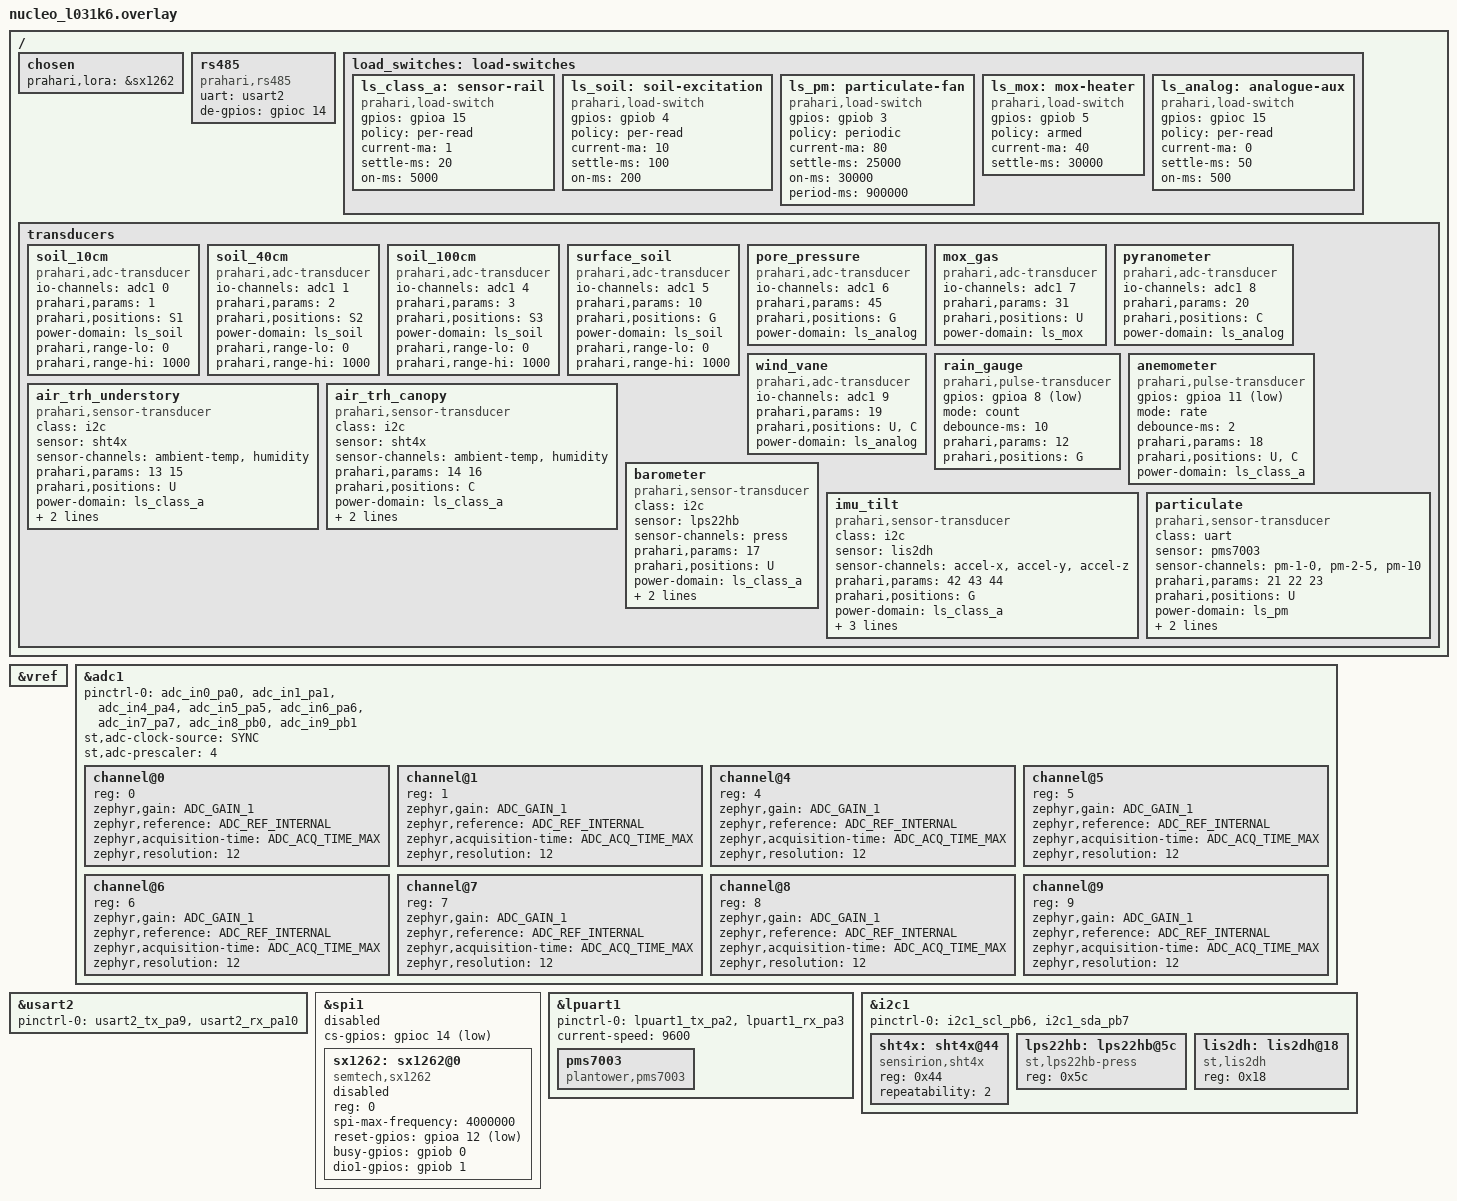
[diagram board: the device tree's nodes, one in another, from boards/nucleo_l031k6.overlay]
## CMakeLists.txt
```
# PRAHARI Code A — pod firmware (L1).  One image for every pod position.
# SPDX-License-Identifier: Apache-2.0
cmake_minimum_required(VERSION 3.20.0)
find_package(Zephyr REQUIRED HINTS $ENV{ZEPHYR_BASE})
project(prahari_pod LANGUAGES C)

target_include_directories(app PRIVATE include)

# Hardware-independent modules (also compiled into the ztest suites).
target_sources(app PRIVATE
  src/pod_position.c
  src/xdcr.c
  src/power.c
  src/pulse.c
  src/sampler.c
  src/calib.c
  src/median5.c
  src/zgate.c
  src/derive.c
  src/pipeline.c
  src/wire.c
  src/rs485.c
  src/lora_slot.c
  src/link_cfg.c
)

# Exactly one head-node link (blueprint §4.4).
target_sources_ifdef(CONFIG_PRAHARI_LINK_MODE_W app PRIVATE src/link_w.c)
target_sources_ifdef(CONFIG_PRAHARI_LINK_MODE_R app PRIVATE src/link_r.c)

# Devicetree-generated tables, class drivers and the boot/sampling loop.
target_sources(app PRIVATE
  src/pod_dt_tables.c
  src/drivers/xdcr_adc.c
  src/drivers/xdcr_pulse.c
  src/drivers/xdcr_sensor.c
  src/main.c
)
```

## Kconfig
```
# PRAHARI Code A — pod firmware configuration.
# SPDX-License-Identifier: Apache-2.0

mainmenu "PRAHARI pod firmware (Code A)"

choice PRAHARI_POD_POSITION_DEFAULT
	prompt "Default pod position"
	default PRAHARI_POD_POSITION_DEFAULT_S1
	help
	  Compile-time position used when no valid position block is found in
	  EEPROM (or EEPROM lookup is disabled).  Blueprint §4.1: six positions,
	  one design.  The transducer set for each position comes from the
	  devicetree 'prahari,positions' property of every transducer node.

config PRAHARI_POD_POSITION_DEFAULT_S1
	bool "S1  (-10 cm, potted)"
config PRAHARI_POD_POSITION_DEFAULT_S2
	bool "S2  (-40 cm, potted)"
config PRAHARI_POD_POSITION_DEFAULT_S3
	bool "S3  (-100 cm, potted)"
config PRAHARI_POD_POSITION_DEFAULT_G
	bool "G   (ground, 0 m)"
config PRAHARI_POD_POSITION_DEFAULT_U
	bool "U   (understory, ~2 m)"
config PRAHARI_POD_POSITION_DEFAULT_C
	bool "C   (canopy / mast top, ~10 m)"
endchoice

config PRAHARI_POD_POSITION_FROM_EEPROM
	bool "Read pod position from the EEPROM config block at boot"
	default y
	depends on EEPROM
	help
	  Boot-time selection: a 5-byte block at EEPROM offset 0
	  ('P','D', version, position, CRC-8).  Falls back to the Kconfig
	  default when the block is blank or fails validation.

config PRAHARI_SAMPLE_PERIOD_S
	int "Acquisition cadence for per-read transducers (seconds)"
	range 1 3600
	default 60
	help
	  Blueprint §4.3 "sample at configured cadence".  Transducers on a
	  'periodic' load switch (e.g. the particulate fan) are read on their
	  own duty cycle from §3.4 instead.

config PRAHARI_RAIL_BUDGET_MA
	int "Switched 3.3 V rail budget (mA), 0 = unenforced"
	default 0
	help
	  Upper bound on the summed active current of all load switches that
	  are on at once.  Not specified in the blueprint; set it from the pod
	  board's 12 V -> 3.3 V buck rating once that is chosen.  A request
	  that would exceed the budget is refused (-EBUSY); periodic windows
	  are deferred to the next tick.

config PRAHARI_MOX_ARMED_AT_BOOT
	bool "Arm MOX gas heater(s) at boot"
	default n
	help
	  Blueprint §3.4: the MOX heater is "on only when armed".  Arming is
	  meant to come from the head node; this only sets the boot state.

config PRAHARI_MAX_CHANNELS
	int "Maximum in-situ channels one pod processes"
	range 4 32
	default 12
	help
	  Sizes the median-of-5 and z-score windows (RAM).  A pod position
	  with more parameters than this fails pipeline init.

config PRAHARI_ZGATE_WINDOW
	int "Anomaly-gate rolling window (samples)"
	range 4 32
	default 12
	help
	  Blueprint §4.3: z-score against a rolling mean.  At the default
	  60 s cadence this is 12 minutes — the only history the pod keeps.

config PRAHARI_ZGATE_THRESHOLD_CENTI
	int "Anomaly-gate |z| threshold, hundredths"
	default 300

config PRAHARI_ZGATE_STD_FLOOR_PERMILLE
	int "Anomaly-gate std floor as permille of |mean|"
	default 10
	help
	  Keeps a flat signal from making every LSB of noise a 'z = inf'
	  anomaly.  Absolute floor is 1 milli-unit.

config PRAHARI_EEPROM_CALIB_OFFSET
	int "EEPROM offset of the calibration table"
	default 16
	help
	  Blueprint §4.3: two-point coefficients in EEPROM.  Table format in
	  include/prahari/calib.h; up to 16 entries (277 bytes).

choice PRAHARI_LINK_MODE
	prompt "Head-node link (blueprint §4.4)"
	default PRAHARI_LINK_MODE_W
	help
	  A pod is wired OR radio, set by whether it can power itself (§4.4).
	  Exactly one link stack is built into the image.

config PRAHARI_LINK_MODE_W
	bool "Mode W — wired: RS-485 half-duplex multi-drop, polled slave"
	select UART_INTERRUPT_DRIVEN
	help
	  Head node is bus master (§5.2 sweep).  Needs an enabled /rs485
	  node (prahari,rs485) in the board overlay.

config PRAHARI_LINK_MODE_R
	bool "Mode R — radio: LoRa SX1262, scheduled slot"
	select SPI
	select LORA
	help
	  Reports in a TDMA slot after the head node's beacon.  Needs an
	  enabled semtech,sx1262 node named by 'chosen prahari,lora'.
endchoice

config PRAHARI_LINK_ADDR
	int "Default RS-485 address / pod identity (1..247)"
	range 1 247
	default 1
	help
	  Overridden by the EEPROM link block ('L','K') when present.

config PRAHARI_LINK_SLOT
	int "Default TDMA slot (Mode R)"
	range 0 255
	default 0

config PRAHARI_RS485_IDLE_GAP_MS
	int "RS-485 inter-frame idle gap that resets the parser (ms)"
	default 20
	depends on PRAHARI_LINK_MODE_W

if PRAHARI_LINK_MODE_R

config PRAHARI_LORA_FREQ_HZ
	int "LoRa centre frequency (Hz)"
	default 866000000
	help
	  §6.2 / §7.3: 865-867 MHz ISM, licence-free in India.

config PRAHARI_LORA_SF
	int "LoRa spreading factor"
	range 7 10
	default 9
	help
	  §7.3: SF7-SF10, 125 kHz.  Fixed per pod; adaptive SF is the head node's call.

config PRAHARI_LORA_TX_DBM
	int "LoRa TX power (dBm)"
	default 14

config PRAHARI_SLOT_SUPERFRAME_MS
	int "TDMA superframe (ms)"
	default 60000
	help
	  One round per acquisition cadence.

config PRAHARI_SLOT_MS
	int "Slot length (ms)"
	default 2000
	help
	  A full pod report (~110 B) at SF10/125 kHz is ~0.8 s on air.

config PRAHARI_SLOT_N
	int "Number of pod slots per superframe"
	default 8

config PRAHARI_SLOT_BEACON_MS
	int "Beacon airtime reserved at superframe start (ms)"
	default 500

config PRAHARI_SLOT_GUARD_MS
	int "Guard time around slot edges (ms)"
	default 50

config PRAHARI_SLOT_HOLDOVER_MS
	int "Time without a beacon before the pod counts as unsynced (ms)"
	default 3600000
	help
	  The pod keeps its free-running schedule regardless; this only
	  changes what it reports about itself.

endif # PRAHARI_LINK_MODE_R

config PRAHARI_FRAME_PRINT
	bool "Print each completed frame on the console"
	default y
	depends on PRINTK

# The SX1262 is driven by Zephyr's native backend (no loramac-node /
# lora-basics-modem module in this workspace).  The legacy module-backed
# driver symbol defaults on whenever the DT node exists; keep it off.
configdefault LORA_SX126X
	default n

source "Kconfig.zephyr"
```

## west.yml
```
# West manifest for PRAHARI Code A — pod firmware (L1).
#
# Topology: T2 ("application as manifest repository").  The workspace root
# is code_a_pod_firmware/; this directory (app/) is the manifest repo and
# the Zephyr application.  Zephyr itself and the HAL modules are checked
# out as siblings of app/ by `west update` and are NOT part of the
# deliverable source.
#
# Zephyr v4.4.2 — newest stable tag at time of setup (2026-09-09);
# 4.4 is the first release of the new six-month cadence and the LTS
# candidate.  Pinned to a tag, never a branch.  Requires Zephyr SDK 1.0.1
# (zephyr/SDK_VERSION).
#
# Only the modules the STM32L0 pod target needs are imported.  Add to the
# allowlist deliberately; do not remove it.
manifest:
  remotes:
    - name: zephyrproject-rtos
      url-base: https://github.com/zephyrproject-rtos

  projects:
    - name: zephyr
      remote: zephyrproject-rtos
      revision: v4.4.2
      import:
        name-allowlist:
          - cmsis        # legacy CMSIS headers, still referenced by hal_stm32
          - cmsis_6      # CMSIS 6 core headers used by Zephyr arch/arm
          - hal_stm32    # STM32Cube LL/HAL + dts pinctrl for STM32L0

  self:
    path: app
```

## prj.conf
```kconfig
# PRAHARI Code A — base configuration (all positions, one image).
CONFIG_GPIO=y
CONFIG_ADC=y
CONFIG_I2C=y
CONFIG_SERIAL=y
CONFIG_SENSOR=y
CONFIG_EEPROM=y

# Keep the image small: STM32L031 has 32 KB flash / 8 KB RAM.
CONFIG_SIZE_OPTIMIZATIONS=y
CONFIG_MAIN_STACK_SIZE=1280
CONFIG_ISR_STACK_SIZE=512
CONFIG_IDLE_STACK_SIZE=256
CONFIG_SYSTEM_WORKQUEUE_STACK_SIZE=512
CONFIG_LOG=n
CONFIG_PRINTK=y
CONFIG_CONSOLE=y
CONFIG_UART_CONSOLE=y
CONFIG_ASSERT=n
```

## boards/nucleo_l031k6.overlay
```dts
/*
 * PRAHARI pod firmware on the STM32L031K6 Nucleo-32 (SoC = blueprint §4.2).
 *
 * ONE image, all six positions: every transducer that any position can
 * carry is declared here; the firmware enables only those whose
 * "prahari,positions" includes the pod's resolved position.
 *
 * Reference parts (NOT a BOM decision — swap the sensor node, keep the
 * transducer node): SHT4x air T/RH, LPS22HB pressure, LIS2DH accel/tilt,
 * PMS7003 particulate.  Analogue inputs are generic.
 *
 * Pin plan (Nucleo-32): USART2 on PA9/PA10 carries the RS-485 transceiver
 * (Mode W) — and the console in this dev build, which on real hardware
 * must be off (-DCONFIG_UART_CONSOLE=n) so printk never hits the bus.
 * LPUART1 PA2/PA3 = particulate sensor.  I2C1 PB6/PB7.  RS-485 DE PC14.
 *
 * Mode R on this 32-pin package needs SPI1 PA5/6/7 + PA12/PB0/PB1, which
 * the ADC population uses: boards/nucleo_l031k6_mode_r.overlay
 * (EXTRA_DTC_OVERLAY_FILE) enables the radio and disables those
 * transducers.  The real L051 pod board is pinned out for its population.
 *
 * SPDX-License-Identifier: Apache-2.0
 */
#include <zephyr/dt-bindings/adc/adc.h>
#include <zephyr/dt-bindings/gpio/gpio.h>

/ {
	chosen {
		prahari,lora = &sx1262;
	};

	/* Mode W transceiver: DE/RE on PC14 (LSE pin, unused as oscillator). */
	rs485: rs485 {
		compatible = "prahari,rs485";
		uart = <&usart2>;
		de-gpios = <&gpioc 14 GPIO_ACTIVE_HIGH>;
	};

	/* Blueprint §3.4 switched rails.  Child index = power-domain number. */
	load_switches: load-switches {
		ls_class_a: sensor-rail {
			/* Air T/RH, pressure, IMU: <1 mA.  §3.4 says "continuous is
			 * acceptable" but the rule is nothing energised between reads,
			 * so per-read here; change policy to "hold" to keep it up. */
			compatible = "prahari,load-switch";
			gpios = <&gpioa 15 GPIO_ACTIVE_HIGH>;
			policy = "per-read";
			current-ma = <1>;
			settle-ms = <20>;
			on-ms = <5000>;
		};
		ls_soil: soil-excitation {
			/* §3.4: ~10 mA, 200 ms per read */
			compatible = "prahari,load-switch";
			gpios = <&gpiob 4 GPIO_ACTIVE_HIGH>;
			policy = "per-read";
			current-ma = <10>;
			settle-ms = <100>;
			on-ms = <200>;
		};
		ls_pm: particulate-fan {
			/* §3.4: ~80 mA, 30 s every 15 min.  Read at 25 s, off at 30 s. */
			compatible = "prahari,load-switch";
			gpios = <&gpiob 3 GPIO_ACTIVE_HIGH>;   /* Nucleo LD3: fan window visible */
			policy = "periodic";
			current-ma = <80>;
			settle-ms = <25000>;
			on-ms = <30000>;
			period-ms = <900000>;
		};
		ls_mox: mox-heater {
			/* §3.4: ~40 mA, on only when armed.  Warm-up not specified in
			 * the blueprint: 30 s is a placeholder for the chosen element. */
			compatible = "prahari,load-switch";
			gpios = <&gpiob 5 GPIO_ACTIVE_HIGH>;
			policy = "armed";
			current-ma = <40>;
			settle-ms = <30000>;
		};
		ls_analog: analogue-aux {
			/* Pore-pressure, wind vane, pyranometer front-ends.  Draw not in
			 * §3.4 table (0 = unbudgeted until the parts are chosen). */
			compatible = "prahari,load-switch";
			gpios = <&gpioc 15 GPIO_ACTIVE_HIGH>;
			policy = "per-read";
			current-ma = <0>;
			settle-ms = <50>;
			on-ms = <500>;
		};
	};

	/* Parameter IDs: docs/reference/prahari_parameters.md (P-numbers). */
	transducers: transducers {
		/* ---- class C: analogue into ADC ---- */
		soil_10cm {
			/* Capacitive probe lead 1 -> P1.  P4/P7 (temp, EC) need extra
			 * analogue lines or a digital probe: add io-channels + params. */
			compatible = "prahari,adc-transducer";
			io-channels = <&adc1 0>;
			prahari,params = <1>;
			prahari,positions = "S1";
			power-domain = <&ls_soil>;
			prahari,range-lo = <0>;
			prahari,range-hi = <1000>;
		};
		soil_40cm {
			compatible = "prahari,adc-transducer";
			io-channels = <&adc1 1>;
			prahari,params = <2>;
			prahari,positions = "S2";
			power-domain = <&ls_soil>;
			prahari,range-lo = <0>;
			prahari,range-hi = <1000>;
		};
		soil_100cm {
			compatible = "prahari,adc-transducer";
			io-channels = <&adc1 4>;
			prahari,params = <3>;
			prahari,positions = "S3";
			power-domain = <&ls_soil>;
			prahari,range-lo = <0>;
			prahari,range-hi = <1000>;
		};
		surface_soil {
			/* §11.4 G: surface soil moisture 0-5 cm -> P10 */
			compatible = "prahari,adc-transducer";
			io-channels = <&adc1 5>;
			prahari,params = <10>;
			prahari,positions = "G";
			power-domain = <&ls_soil>;
			prahari,range-lo = <0>;
			prahari,range-hi = <1000>;
		};
		pore_pressure {
			/* Requested at G; blueprint §11.4 lists it on the R3 slope pod. */
			compatible = "prahari,adc-transducer";
			io-channels = <&adc1 6>;
			prahari,params = <45>;
			prahari,positions = "G";
			power-domain = <&ls_analog>;
		};
		mox_gas {
			/* Analogue MOX element (blueprint class C variant) -> P31 TVOC
			 * index after calibration.  Heater on the armed rail. */
			compatible = "prahari,adc-transducer";
			io-channels = <&adc1 7>;
			prahari,params = <31>;
			prahari,positions = "U";
			power-domain = <&ls_mox>;
		};
		pyranometer {
			/* Global solar irradiance -> P20 (canopy, needs open sky) */
			compatible = "prahari,adc-transducer";
			io-channels = <&adc1 8>;
			prahari,params = <20>;
			prahari,positions = "C";
			power-domain = <&ls_analog>;
		};
		wind_vane {
			/* CONFLICT FLAGGED: blueprint §3.1 lists the wind vane under class
			 * D (pulse); a potentiometer vane is analogue.  Modelled as class C
			 * here; change compatible to prahari,pulse-transducer if the chosen
			 * vane is an encoder.  Bearing -> sin/cos happens downstream. */
			compatible = "prahari,adc-transducer";
			io-channels = <&adc1 9>;
			prahari,params = <19>;
			prahari,positions = "U", "C";
			power-domain = <&ls_analog>;
		};

		/* ---- class D: pulse / interrupt ---- */
		rain_gauge {
			/* Tipping bucket -> P12 accumulation (tips; mm at calibration).
			 * No power-domain on purpose: §3.4 passive, never switched. */
			compatible = "prahari,pulse-transducer";
			gpios = <&gpioa 8 (GPIO_PULL_UP | GPIO_ACTIVE_LOW)>;
			mode = "count";
			debounce-ms = <10>;
			prahari,params = <12>;
			prahari,positions = "G";
		};
		anemometer {
			/* Cup anemometer reed switch -> P18 (pulses per cycle; m/s at cal) */
			compatible = "prahari,pulse-transducer";
			gpios = <&gpioa 11 (GPIO_PULL_UP | GPIO_ACTIVE_LOW)>;
			mode = "rate";
			debounce-ms = <2>;
			prahari,params = <18>;
			prahari,positions = "U", "C";
			power-domain = <&ls_class_a>;
		};

		/* ---- class A: I2C sensors (each pod terminates its own bus) ---- */
		air_trh_understory {
			/* Same physical part as air_trh_canopy; which node is active
			 * depends on position, so P13/P15 vs P14/P16 is a config fact. */
			compatible = "prahari,sensor-transducer";
			class = "i2c";
			sensor = <&sht4x>;
			sensor-channels = "ambient-temp", "humidity";
			prahari,params = <13 15>;
			prahari,positions = "U";
			power-domain = <&ls_class_a>;
			prahari,range-lo = <(-40000) 0>;
			prahari,range-hi = <60000 100000>;
		};
		air_trh_canopy {
			compatible = "prahari,sensor-transducer";
			class = "i2c";
			sensor = <&sht4x>;
			sensor-channels = "ambient-temp", "humidity";
			prahari,params = <14 16>;
			prahari,positions = "C";
			power-domain = <&ls_class_a>;
			prahari,range-lo = <(-40000) 0>;
			prahari,range-hi = <60000 100000>;
		};
		barometer {
			compatible = "prahari,sensor-transducer";
			class = "i2c";
			sensor = <&lps22hb>;
			sensor-channels = "press";
			prahari,params = <17>;
			prahari,positions = "U";
			power-domain = <&ls_class_a>;
			prahari,range-lo = <300000>;
			prahari,range-hi = <1100000>;
		};
		imu_tilt {
			/* Bonded to the mast foot: measures the mast, not the air (§3.2) */
			compatible = "prahari,sensor-transducer";
			class = "i2c";
			sensor = <&lis2dh>;
			sensor-channels = "accel-x", "accel-y", "accel-z";
			prahari,params = <42 43 44>;
			prahari,positions = "G";
			power-domain = <&ls_class_a>;
			prahari,range-lo = <(-2000000) (-2000000) (-2000000)>;
			prahari,range-hi = <2000000 2000000 2000000>;
		};

		/* ---- class B: UART ---- */
		particulate {
			compatible = "prahari,sensor-transducer";
			class = "uart";
			sensor = <&pms7003>;
			sensor-channels = "pm-1-0", "pm-2-5", "pm-10";
			prahari,params = <21 22 23>;
			prahari,positions = "U";
			power-domain = <&ls_pm>;
			prahari,range-lo = <0 0 0>;
			prahari,range-hi = <1000000 1000000 1000000>;
		};
	};
};

/* Own supply rail (§4.3 self-report) via the internal reference. */
&vref {
	status = "okay";
};

&adc1 {
	pinctrl-0 = <&adc_in0_pa0 &adc_in1_pa1 &adc_in4_pa4 &adc_in5_pa5
		     &adc_in6_pa6 &adc_in7_pa7 &adc_in8_pb0 &adc_in9_pb1>;
	pinctrl-names = "default";
	st,adc-clock-source = "SYNC";
	st,adc-prescaler = <4>;
	status = "okay";
	#address-cells = <1>;
	#size-cells = <0>;

	channel@0 { reg = <0>; zephyr,gain = "ADC_GAIN_1"; zephyr,reference = "ADC_REF_INTERNAL";
		    zephyr,acquisition-time = <ADC_ACQ_TIME_MAX>; zephyr,resolution = <12>; };
	channel@1 { reg = <1>; zephyr,gain = "ADC_GAIN_1"; zephyr,reference = "ADC_REF_INTERNAL";
		    zephyr,acquisition-time = <ADC_ACQ_TIME_MAX>; zephyr,resolution = <12>; };
	channel@4 { reg = <4>; zephyr,gain = "ADC_GAIN_1"; zephyr,reference = "ADC_REF_INTERNAL";
		    zephyr,acquisition-time = <ADC_ACQ_TIME_MAX>; zephyr,resolution = <12>; };
	channel@5 { reg = <5>; zephyr,gain = "ADC_GAIN_1"; zephyr,reference = "ADC_REF_INTERNAL";
		    zephyr,acquisition-time = <ADC_ACQ_TIME_MAX>; zephyr,resolution = <12>; };
	channel@6 { reg = <6>; zephyr,gain = "ADC_GAIN_1"; zephyr,reference = "ADC_REF_INTERNAL";
		    zephyr,acquisition-time = <ADC_ACQ_TIME_MAX>; zephyr,resolution = <12>; };
	channel@7 { reg = <7>; zephyr,gain = "ADC_GAIN_1"; zephyr,reference = "ADC_REF_INTERNAL";
		    zephyr,acquisition-time = <ADC_ACQ_TIME_MAX>; zephyr,resolution = <12>; };
	channel@8 { reg = <8>; zephyr,gain = "ADC_GAIN_1"; zephyr,reference = "ADC_REF_INTERNAL";
		    zephyr,acquisition-time = <ADC_ACQ_TIME_MAX>; zephyr,resolution = <12>; };
	channel@9 { reg = <9>; zephyr,gain = "ADC_GAIN_1"; zephyr,reference = "ADC_REF_INTERNAL";
		    zephyr,acquisition-time = <ADC_ACQ_TIME_MAX>; zephyr,resolution = <12>; };
};

/* Console off the VCP pins so LPUART1 can take PA2/PA3. */
&usart2 {
	pinctrl-0 = <&usart2_tx_pa9 &usart2_rx_pa10>;
	pinctrl-names = "default";
};

/* SPI1 shares PA5/6/7 with ADC in5/6/7: off unless the Mode R overlay
 * enables it (and disables those ADC transducers). */
&spi1 {
	status = "disabled";
	cs-gpios = <&gpioc 14 GPIO_ACTIVE_LOW>;

	sx1262: sx1262@0 {
		compatible = "semtech,sx1262";
		reg = <0>;
		spi-max-frequency = <4000000>;
		reset-gpios = <&gpioa 12 GPIO_ACTIVE_LOW>;
		busy-gpios = <&gpiob 0 GPIO_ACTIVE_HIGH>;
		dio1-gpios = <&gpiob 1 GPIO_ACTIVE_HIGH>;
		status = "disabled";
	};
};

&lpuart1 {
	pinctrl-0 = <&lpuart1_tx_pa2 &lpuart1_rx_pa3>;
	pinctrl-names = "default";
	current-speed = <9600>;
	status = "okay";

	pms7003: pms7003 {
		compatible = "plantower,pms7003";
	};
};

&i2c1 {
	pinctrl-0 = <&i2c1_scl_pb6 &i2c1_sda_pb7>;
	pinctrl-names = "default";
	status = "okay";

	sht4x: sht4x@44 {
		compatible = "sensirion,sht4x";
		reg = <0x44>;
		repeatability = <2>;
	};
	lps22hb: lps22hb@5c {
		compatible = "st,lps22hb-press";
		reg = <0x5c>;
	};
	lis2dh: lis2dh@18 {
		compatible = "st,lis2dh";
		reg = <0x18>;
	};
};
```

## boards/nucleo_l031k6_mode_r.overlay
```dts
/*
 * Mode R on the Nucleo-32 L031K6: EXTRA_DTC_OVERLAY_FILE for
 * -DCONFIG_PRAHARI_LINK_MODE_R=y.  The 32-pin package cannot carry the
 * whole dev population plus a radio, so the transducers on the SPI /
 * control pins are disabled here.  Dev-board limitation only.
 * SPDX-License-Identifier: Apache-2.0
 */
&spi1 {
	status = "okay";
};

&sx1262 {
	status = "okay";
};

&rs485 {
	status = "disabled";
};

&adc1 {
	pinctrl-0 = <&adc_in0_pa0 &adc_in1_pa1 &adc_in4_pa4>;
};

&{/transducers/surface_soil} { status = "disabled"; };
&{/transducers/pore_pressure} { status = "disabled"; };
&{/transducers/mox_gas} { status = "disabled"; };
&{/transducers/pyranometer} { status = "disabled"; };
&{/transducers/wind_vane} { status = "disabled"; };
```

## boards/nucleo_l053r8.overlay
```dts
/*
 * SIZE STAND-IN ONLY: same population as nucleo_l031k6 on the Nucleo-64
 * L053R8 (64 KB flash, same L0 family) to measure the image on a 64 KB part
 * until the L051 decision and its custom board definition exist.  Not a
 * target.  Enough pins here for both link modes without disabling anything.
 *
 * ONE image, all six positions: every transducer that any position can
 * carry is declared here; the firmware enables only those whose
 * "prahari,positions" includes the pod's resolved position.
 *
 * Reference parts (NOT a BOM decision — swap the sensor node, keep the
 * transducer node): SHT4x air T/RH, LPS22HB pressure, LIS2DH accel/tilt,
 * PMS7003 particulate.  Analogue inputs are generic.
 *
 * Pin plan (Nucleo-32): USART2 on PA9/PA10 carries the RS-485 transceiver
 * (Mode W) — and the console in this dev build, which on real hardware
 * must be off (-DCONFIG_UART_CONSOLE=n) so printk never hits the bus.
 * LPUART1 PA2/PA3 = particulate sensor.  I2C1 PB6/PB7.  RS-485 DE PC14.
 *
 * Mode R on this 32-pin package needs SPI1 PA5/6/7 + PA12/PB0/PB1, which
 * the ADC population uses: boards/nucleo_l031k6_mode_r.overlay
 * (EXTRA_DTC_OVERLAY_FILE) enables the radio and disables those
 * transducers.  The real L051 pod board is pinned out for its population.
 *
 * SPDX-License-Identifier: Apache-2.0
 */
#include <zephyr/dt-bindings/adc/adc.h>
#include <zephyr/dt-bindings/gpio/gpio.h>

/ {
	chosen {
		prahari,lora = &sx1262;
	};

	/* Mode W transceiver: DE/RE on PC14 (LSE pin, unused as oscillator). */
	rs485: rs485 {
		compatible = "prahari,rs485";
		uart = <&usart1>;
		de-gpios = <&gpioc 8 GPIO_ACTIVE_HIGH>;
	};

	/* Blueprint §3.4 switched rails.  Child index = power-domain number. */
	load_switches: load-switches {
		ls_class_a: sensor-rail {
			/* Air T/RH, pressure, IMU: <1 mA.  §3.4 says "continuous is
			 * acceptable" but the rule is nothing energised between reads,
			 * so per-read here; change policy to "hold" to keep it up. */
			compatible = "prahari,load-switch";
			gpios = <&gpioa 15 GPIO_ACTIVE_HIGH>;
			policy = "per-read";
			current-ma = <1>;
			settle-ms = <20>;
			on-ms = <5000>;
		};
		ls_soil: soil-excitation {
			/* §3.4: ~10 mA, 200 ms per read */
			compatible = "prahari,load-switch";
			gpios = <&gpiob 4 GPIO_ACTIVE_HIGH>;
			policy = "per-read";
			current-ma = <10>;
			settle-ms = <100>;
			on-ms = <200>;
		};
		ls_pm: particulate-fan {
			/* §3.4: ~80 mA, 30 s every 15 min.  Read at 25 s, off at 30 s. */
			compatible = "prahari,load-switch";
			gpios = <&gpiob 3 GPIO_ACTIVE_HIGH>;   /* Nucleo LD3: fan window visible */
			policy = "periodic";
			current-ma = <80>;
			settle-ms = <25000>;
			on-ms = <30000>;
			period-ms = <900000>;
		};
		ls_mox: mox-heater {
			/* §3.4: ~40 mA, on only when armed.  Warm-up not specified in
			 * the blueprint: 30 s is a placeholder for the chosen element. */
			compatible = "prahari,load-switch";
			gpios = <&gpiob 5 GPIO_ACTIVE_HIGH>;
			policy = "armed";
			current-ma = <40>;
			settle-ms = <30000>;
		};
		ls_analog: analogue-aux {
			/* Pore-pressure, wind vane, pyranometer front-ends.  Draw not in
			 * §3.4 table (0 = unbudgeted until the parts are chosen). */
			compatible = "prahari,load-switch";
			gpios = <&gpioc 15 GPIO_ACTIVE_HIGH>;
			policy = "per-read";
			current-ma = <0>;
			settle-ms = <50>;
			on-ms = <500>;
		};
	};

	/* Parameter IDs: docs/reference/prahari_parameters.md (P-numbers). */
	transducers: transducers {
		/* ---- class C: analogue into ADC ---- */
		soil_10cm {
			/* Capacitive probe lead 1 -> P1.  P4/P7 (temp, EC) need extra
			 * analogue lines or a digital probe: add io-channels + params. */
			compatible = "prahari,adc-transducer";
			io-channels = <&adc1 0>;
			prahari,params = <1>;
			prahari,positions = "S1";
			power-domain = <&ls_soil>;
			prahari,range-lo = <0>;
			prahari,range-hi = <1000>;
		};
		soil_40cm {
			compatible = "prahari,adc-transducer";
			io-channels = <&adc1 1>;
			prahari,params = <2>;
			prahari,positions = "S2";
			power-domain = <&ls_soil>;
			prahari,range-lo = <0>;
			prahari,range-hi = <1000>;
		};
		soil_100cm {
			compatible = "prahari,adc-transducer";
			io-channels = <&adc1 4>;
			prahari,params = <3>;
			prahari,positions = "S3";
			power-domain = <&ls_soil>;
			prahari,range-lo = <0>;
			prahari,range-hi = <1000>;
		};
		surface_soil {
			/* §11.4 G: surface soil moisture 0-5 cm -> P10 */
			compatible = "prahari,adc-transducer";
			io-channels = <&adc1 5>;
			prahari,params = <10>;
			prahari,positions = "G";
			power-domain = <&ls_soil>;
			prahari,range-lo = <0>;
			prahari,range-hi = <1000>;
		};
		pore_pressure {
			/* Requested at G; blueprint §11.4 lists it on the R3 slope pod. */
			compatible = "prahari,adc-transducer";
			io-channels = <&adc1 6>;
			prahari,params = <45>;
			prahari,positions = "G";
			power-domain = <&ls_analog>;
		};
		mox_gas {
			/* Analogue MOX element (blueprint class C variant) -> P31 TVOC
			 * index after calibration.  Heater on the armed rail. */
			compatible = "prahari,adc-transducer";
			io-channels = <&adc1 7>;
			prahari,params = <31>;
			prahari,positions = "U";
			power-domain = <&ls_mox>;
		};
		pyranometer {
			/* Global solar irradiance -> P20 (canopy, needs open sky) */
			compatible = "prahari,adc-transducer";
			io-channels = <&adc1 8>;
			prahari,params = <20>;
			prahari,positions = "C";
			power-domain = <&ls_analog>;
		};
		wind_vane {
			/* CONFLICT FLAGGED: blueprint §3.1 lists the wind vane under class
			 * D (pulse); a potentiometer vane is analogue.  Modelled as class C
			 * here; change compatible to prahari,pulse-transducer if the chosen
			 * vane is an encoder.  Bearing -> sin/cos happens downstream. */
			compatible = "prahari,adc-transducer";
			io-channels = <&adc1 9>;
			prahari,params = <19>;
			prahari,positions = "U", "C";
			power-domain = <&ls_analog>;
		};

		/* ---- class D: pulse / interrupt ---- */
		rain_gauge {
			/* Tipping bucket -> P12 accumulation (tips; mm at calibration).
			 * No power-domain on purpose: §3.4 passive, never switched. */
			compatible = "prahari,pulse-transducer";
			gpios = <&gpioa 8 (GPIO_PULL_UP | GPIO_ACTIVE_LOW)>;
			mode = "count";
			debounce-ms = <10>;
			prahari,params = <12>;
			prahari,positions = "G";
		};
		anemometer {
			/* Cup anemometer reed switch -> P18 (pulses per cycle; m/s at cal) */
			compatible = "prahari,pulse-transducer";
			gpios = <&gpioa 11 (GPIO_PULL_UP | GPIO_ACTIVE_LOW)>;
			mode = "rate";
			debounce-ms = <2>;
			prahari,params = <18>;
			prahari,positions = "U", "C";
			power-domain = <&ls_class_a>;
		};

		/* ---- class A: I2C sensors (each pod terminates its own bus) ---- */
		air_trh_understory {
			/* Same physical part as air_trh_canopy; which node is active
			 * depends on position, so P13/P15 vs P14/P16 is a config fact. */
			compatible = "prahari,sensor-transducer";
			class = "i2c";
			sensor = <&sht4x>;
			sensor-channels = "ambient-temp", "humidity";
			prahari,params = <13 15>;
			prahari,positions = "U";
			power-domain = <&ls_class_a>;
			prahari,range-lo = <(-40000) 0>;
			prahari,range-hi = <60000 100000>;
		};
		air_trh_canopy {
			compatible = "prahari,sensor-transducer";
			class = "i2c";
			sensor = <&sht4x>;
			sensor-channels = "ambient-temp", "humidity";
			prahari,params = <14 16>;
			prahari,positions = "C";
			power-domain = <&ls_class_a>;
			prahari,range-lo = <(-40000) 0>;
			prahari,range-hi = <60000 100000>;
		};
		barometer {
			compatible = "prahari,sensor-transducer";
			class = "i2c";
			sensor = <&lps22hb>;
			sensor-channels = "press";
			prahari,params = <17>;
			prahari,positions = "U";
			power-domain = <&ls_class_a>;
			prahari,range-lo = <300000>;
			prahari,range-hi = <1100000>;
		};
		imu_tilt {
			/* Bonded to the mast foot: measures the mast, not the air (§3.2) */
			compatible = "prahari,sensor-transducer";
			class = "i2c";
			sensor = <&lis2dh>;
			sensor-channels = "accel-x", "accel-y", "accel-z";
			prahari,params = <42 43 44>;
			prahari,positions = "G";
			power-domain = <&ls_class_a>;
			prahari,range-lo = <(-2000000) (-2000000) (-2000000)>;
			prahari,range-hi = <2000000 2000000 2000000>;
		};

		/* ---- class B: UART ---- */
		particulate {
			compatible = "prahari,sensor-transducer";
			class = "uart";
			sensor = <&pms7003>;
			sensor-channels = "pm-1-0", "pm-2-5", "pm-10";
			prahari,params = <21 22 23>;
			prahari,positions = "U";
			power-domain = <&ls_pm>;
			prahari,range-lo = <0 0 0>;
			prahari,range-hi = <1000000 1000000 1000000>;
		};
	};
};

/* Own supply rail (§4.3 self-report) via the internal reference. */
&vref {
	status = "okay";
};

&adc1 {
	pinctrl-0 = <&adc_in0_pa0 &adc_in1_pa1 &adc_in4_pa4 &adc_in5_pa5
		     &adc_in6_pa6 &adc_in7_pa7 &adc_in8_pb0 &adc_in9_pb1>;
	pinctrl-names = "default";
	st,adc-clock-source = "SYNC";
	st,adc-prescaler = <4>;
	status = "okay";
	#address-cells = <1>;
	#size-cells = <0>;

	channel@0 { reg = <0>; zephyr,gain = "ADC_GAIN_1"; zephyr,reference = "ADC_REF_INTERNAL";
		    zephyr,acquisition-time = <ADC_ACQ_TIME_MAX>; zephyr,resolution = <12>; };
	channel@1 { reg = <1>; zephyr,gain = "ADC_GAIN_1"; zephyr,reference = "ADC_REF_INTERNAL";
		    zephyr,acquisition-time = <ADC_ACQ_TIME_MAX>; zephyr,resolution = <12>; };
	channel@4 { reg = <4>; zephyr,gain = "ADC_GAIN_1"; zephyr,reference = "ADC_REF_INTERNAL";
		    zephyr,acquisition-time = <ADC_ACQ_TIME_MAX>; zephyr,resolution = <12>; };
	channel@5 { reg = <5>; zephyr,gain = "ADC_GAIN_1"; zephyr,reference = "ADC_REF_INTERNAL";
		    zephyr,acquisition-time = <ADC_ACQ_TIME_MAX>; zephyr,resolution = <12>; };
	channel@6 { reg = <6>; zephyr,gain = "ADC_GAIN_1"; zephyr,reference = "ADC_REF_INTERNAL";
		    zephyr,acquisition-time = <ADC_ACQ_TIME_MAX>; zephyr,resolution = <12>; };
	channel@7 { reg = <7>; zephyr,gain = "ADC_GAIN_1"; zephyr,reference = "ADC_REF_INTERNAL";
		    zephyr,acquisition-time = <ADC_ACQ_TIME_MAX>; zephyr,resolution = <12>; };
	channel@8 { reg = <8>; zephyr,gain = "ADC_GAIN_1"; zephyr,reference = "ADC_REF_INTERNAL";
		    zephyr,acquisition-time = <ADC_ACQ_TIME_MAX>; zephyr,resolution = <12>; };
	channel@9 { reg = <9>; zephyr,gain = "ADC_GAIN_1"; zephyr,reference = "ADC_REF_INTERNAL";
		    zephyr,acquisition-time = <ADC_ACQ_TIME_MAX>; zephyr,resolution = <12>; };
};

/* Stand-in pinout: console stays on the board default USART2 PA2/PA3;
 * RS-485 on USART1 PB6/PB7, DE on PC8. */
&usart1 {
	pinctrl-0 = <&usart1_tx_pb6 &usart1_rx_pb7>;
	pinctrl-names = "default";
	current-speed = <19200>;
	status = "okay";
};

/* SX1262 on SPI2 (PB13/14/15), CS PB12, RESET PC6, BUSY PC7, DIO1 PC9. */
&spi2 {
	pinctrl-0 = <&spi2_sck_pb13 &spi2_miso_pb14 &spi2_mosi_pb15>;
	pinctrl-names = "default";
	status = "okay";
	cs-gpios = <&gpiob 12 GPIO_ACTIVE_LOW>;

	sx1262: sx1262@0 {
		compatible = "semtech,sx1262";
		reg = <0>;
		spi-max-frequency = <4000000>;
		reset-gpios = <&gpioc 6 GPIO_ACTIVE_LOW>;
		busy-gpios = <&gpioc 7 GPIO_ACTIVE_HIGH>;
		dio1-gpios = <&gpioc 9 GPIO_ACTIVE_HIGH>;
	};
};

&lpuart1 {
	pinctrl-0 = <&lpuart1_tx_pb10 &lpuart1_rx_pb11>;
	pinctrl-names = "default";
	current-speed = <9600>;
	status = "okay";

	pms7003: pms7003 {
		compatible = "plantower,pms7003";
	};
};

&i2c1 {
	pinctrl-0 = <&i2c1_scl_pb8 &i2c1_sda_pb9>;
	pinctrl-names = "default";
	status = "okay";

	sht4x: sht4x@44 {
		compatible = "sensirion,sht4x";
		reg = <0x44>;
		repeatability = <2>;
	};
	lps22hb: lps22hb@5c {
		compatible = "st,lps22hb-press";
		reg = <0x5c>;
	};
	lis2dh: lis2dh@18 {
		compatible = "st,lis2dh";
		reg = <0x18>;
	};
};
```

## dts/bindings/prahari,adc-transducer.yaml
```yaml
# Class C (blueprint §3.1): analogue transducer into the MCU ADC.
# One io-channel per parameter, same order as prahari,params.

description: PRAHARI class C transducer (analogue into ADC)

compatible: "prahari,adc-transducer"

include: prahari,transducer-base.yaml

properties:
  io-channels:
    type: phandle-array
    required: true
    description: ADC channel per reported parameter.
```

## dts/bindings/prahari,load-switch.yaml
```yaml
# One switched 3.3 V rail (blueprint §3.4): a load switch under MCU control
# feeding one or more transducers.  Children of the /load-switches node;
# the child index is the power-domain number used by the firmware.
#
# 'policy' enum order MUST match 'enum pwr_policy' in include/prahari/power.h.

description: PRAHARI transducer load switch (switched 3.3 V rail)

compatible: "prahari,load-switch"

include: base.yaml

properties:
  gpios:
    type: phandle-array
    required: true
    description: Load-switch enable pin (active level = rail on).

  current-ma:
    type: int
    required: true
    description: |
      Draw of the transducer(s) on this rail when active, mA
      (blueprint §3.4 table).  0 = not specified / not budgeted.

  policy:
    type: string
    required: true
    enum:
      - "per-read"   # on for the duration of a read, then off
      - "periodic"   # own duty cycle: on for on-ms every period-ms
      - "armed"      # on only while armed (MOX heater)
      - "hold"       # stays on once first acquired (only where §3.4 allows)
    description: Switching policy.

  settle-ms:
    type: int
    default: 0
    description: Time after switch-on before a read is allowed.

  on-ms:
    type: int
    default: 0
    description: |
      periodic: length of each on-window.  Other policies: hard cap on
      continuous on-time (0 = no cap); exceeding it forces the rail off.

  period-ms:
    type: int
    default: 0
    description: periodic only; window repeat interval.
```

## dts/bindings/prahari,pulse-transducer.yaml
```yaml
# Class D (blueprint §3.1): pulse / interrupt transducer on a GPIO.

description: PRAHARI class D transducer (pulse / interrupt)

compatible: "prahari,pulse-transducer"

include: prahari,transducer-base.yaml

properties:
  gpios:
    type: phandle-array
    required: true
    description: Pulse input; use GPIO_ACTIVE_* to select the counted edge.

  mode:
    type: string
    required: true
    enum:
      - "count"   # cumulative counter (tipping rain gauge -> P12 accumulation)
      - "rate"    # pulses since the previous read (cup anemometer -> P18)
    description: What the read returns.  Order must match xdcr_pulse.c.

  debounce-ms:
    type: int
    default: 10
    description: Edges closer than this to the previous accepted edge are ignored.
```

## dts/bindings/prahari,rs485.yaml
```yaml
# Mode W transceiver (blueprint §4.4): the UART the isolated RS-485
# transceiver sits on and its driver-enable pin.  One node at /rs485.

description: PRAHARI RS-485 half-duplex transceiver

compatible: "prahari,rs485"

include: base.yaml

properties:
  uart:
    type: phandle
    required: true
    description: UART wired to the transceiver (must be enabled).

  de-gpios:
    type: phandle-array
    required: true
    description: Driver-enable (DE, and /RE tied to it). Active = transmit.
```

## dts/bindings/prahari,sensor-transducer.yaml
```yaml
# Class A (I2C) or class B (UART) digital transducer exposed through a
# Zephyr sensor driver.  The physical part is whatever the 'sensor'
# phandle points at; this node only maps sensor channels to PRAHARI
# parameter IDs for one pod position.

description: PRAHARI class A/B transducer behind a Zephyr sensor driver

compatible: "prahari,sensor-transducer"

include: prahari,transducer-base.yaml

properties:
  sensor:
    type: phandle
    required: true
    description: The Zephyr sensor device (I2C or UART child node).

  sensor-channels:
    type: string-array
    required: true
    description: |
      Zephyr sensor channel per parameter, same order as prahari,params,
      as the SENSOR_CHAN_ suffix in lower-case with dashes, e.g.
      "ambient-temp", "humidity", "press", "accel-x", "pm-2-5".

  class:
    type: string
    required: true
    enum:
      - "i2c"   # blueprint class A
      - "uart"  # blueprint class B
    description: Blueprint §3.1 interface class of the physical link.
```

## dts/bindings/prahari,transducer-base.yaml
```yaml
# Common properties of every PRAHARI transducer node.  Included by the
# per-class bindings; never used as a compatible on its own.

description: PRAHARI transducer (common properties)

include: base.yaml

properties:
  prahari,params:
    type: array
    required: true
    description: |
      Parameter IDs this transducer reports, one per channel, in channel
      order.  Numbers are the 'P' IDs from docs/reference/prahari_parameters.md
      (PRIMARY in situ, P1..P46).  Never invent one.

  prahari,positions:
    type: string-array
    required: true
    description: |
      Pod positions (blueprint §4.1) at which this transducer is populated:
      any of "S1" "S2" "S3" "G" "U" "C".  The firmware enables the node
      only when the pod's resolved position is listed here.

  power-domain:
    type: phandle
    description: |
      The prahari,load-switch feeding this transducer.  Omit ONLY for a
      transducer that is passive and unpowered (blueprint §3.4: the
      tipping rain gauge).

  prahari,range-lo:
    type: array
    description: |
      Optional.  Lower in-spec bound per parameter (milli-units of the
      parameter unit, after calibration), same order as prahari,params.
      Both range-lo and range-hi must be given together.  Values outside
      [lo, hi] are FLAGGED (XDCR_F_RANGE), never discarded (§4.3).

  prahari,range-hi:
    type: array
    description: Optional.  Upper in-spec bound per parameter; see prahari,range-lo.
```

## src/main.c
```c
/*
 * PRAHARI Code A — pod firmware entry.
 *
 * Boot: resolve position (EEPROM block, else Kconfig) -> bring every load
 * switch OFF -> select the transducers populated at this position ->
 * init them -> loop: tick the power controller once a second, run an
 * acquisition cycle every CONFIG_PRAHARI_SAMPLE_PERIOD_S, read periodic
 * rails (particulate fan) at the end of their own duty window.
 *
 * Each frame then goes through the §4.3 pipeline (calibrate, median-of-5,
 * range gate, z-score gate, derivations, self-report).  The resulting
 * report is printed on the console as the stand-in for the RS-485 / LoRa
 * transport, which is not here yet.
 *
 * Hard boundary: the only history in this image is the anomaly gate's
 * short window.  Antecedent indices, fire-weather cascade, tendencies
 * belong to Code B.
 *
 * SPDX-License-Identifier: Apache-2.0
 */
#include <zephyr/kernel.h>
#include <zephyr/device.h>
#include <zephyr/drivers/eeprom.h>
#include <zephyr/drivers/sensor.h>
#include <zephyr/sys/printk.h>
#include <prahari/calib.h>
#include <prahari/link.h>
#include <prahari/link_cfg.h>
#include <prahari/pipeline.h>
#include <prahari/params.h>
#include <prahari/pod_position.h>
#include <prahari/power.h>
#include <prahari/sampler.h>
#include <prahari/xdcr.h>
#include "pod_dt_tables.h"

#if defined(CONFIG_PRAHARI_POD_POSITION_DEFAULT_S1)
#define POD_POS_DEFAULT POD_POS_S1
#elif defined(CONFIG_PRAHARI_POD_POSITION_DEFAULT_S2)
#define POD_POS_DEFAULT POD_POS_S2
#elif defined(CONFIG_PRAHARI_POD_POSITION_DEFAULT_S3)
#define POD_POS_DEFAULT POD_POS_S3
#elif defined(CONFIG_PRAHARI_POD_POSITION_DEFAULT_G)
#define POD_POS_DEFAULT POD_POS_G
#elif defined(CONFIG_PRAHARI_POD_POSITION_DEFAULT_U)
#define POD_POS_DEFAULT POD_POS_U
#else
#define POD_POS_DEFAULT POD_POS_C
#endif

#define EEPROM_NODE DT_ALIAS(eeprom_0)
#define HAVE_EEPROM_POSITION                                                                       \
	(IS_ENABLED(CONFIG_PRAHARI_POD_POSITION_FROM_EEPROM) && DT_NODE_HAS_STATUS_OKAY(EEPROM_NODE))

#define VREF_NODE DT_NODELABEL(vref)
#define HAVE_VREF DT_NODE_HAS_STATUS_OKAY(VREF_NODE)

static struct pwr_ctl pwr;
static struct pod_frame frame;
static const struct xdcr_desc *selected[POD_XDCR_COUNT];
static struct sampler sampler;
static struct calib_table calib;
static struct pipeline pipeline;
static struct pod_report report;
static uint16_t init_fail_bits;
static struct link_identity link_id;

static uint32_t clk_now(void *ctx)
{
	ARG_UNUSED(ctx);
	return k_uptime_get_32();
}

static void clk_sleep(void *ctx, uint32_t ms)
{
	ARG_UNUSED(ctx);
	k_sleep(K_MSEC(ms));
}

static const struct sampler_clock clock = {.now_ms = clk_now, .sleep_ms = clk_sleep};

static void on_pwr_event(void *ctx, uint8_t dom, enum pwr_event evt)
{
	struct sampler *s = ctx;

	switch (evt) {
	case PWR_EVT_READY:
		if (pod_pwr_domains[dom].policy == PWR_POLICY_PERIODIC) {
			sampler_on_domain_ready(s, dom);
		}
		break;
	case PWR_EVT_TIMEOUT:
		printk("pwr: %s exceeded on-time cap, forced off\n", pod_pwr_domains[dom].name);
		break;
	case PWR_EVT_DEFERRED:
		printk("pwr: %s window deferred (rail budget)\n", pod_pwr_domains[dom].name);
		break;
	default:
		break;
	}
}

/* Head-node command hook (blueprint §3.4: MOX heater on only when armed). */
int pod_gas_arm(bool armed)
{
	int rc = 0;
	uint32_t now = k_uptime_get_32();

	for (uint8_t d = 0; d < POD_PWR_DOMAIN_COUNT; d++) {
		if (pod_pwr_domains[d].policy == PWR_POLICY_ARMED) {
			int r = pwr_arm(&pwr, d, armed, now);

			if (r && !rc) {
				rc = r;
			}
		}
	}
	return rc;
}


static void load_calibration(void)
{
	int rc = -ENOENT;

#if HAVE_EEPROM_POSITION
	const struct device *eep = DEVICE_DT_GET(EEPROM_NODE);
	uint8_t blob[CALIB_BLOB_MAX];

	if (device_is_ready(eep) &&
	    eeprom_read(eep, CONFIG_PRAHARI_EEPROM_CALIB_OFFSET, blob, sizeof(blob)) == 0) {
		rc = calib_table_decode(blob, sizeof(blob), &calib);
	}
#endif
	if (rc == 0) {
		printk("calibration: %u entries from eeprom\n", calib.n);
	} else {
		calib.n = 0;
		printk("calibration: none (%d); raw channels will be marked UNCAL\n", rc);
	}
}

/* §4.3 self-report: own supply rail through the internal reference. */
static bool read_rail_mv(int32_t *mv)
{
#if HAVE_VREF
	const struct device *vref = DEVICE_DT_GET(VREF_NODE);
	struct sensor_value v;

	if (device_is_ready(vref) && sensor_sample_fetch(vref) == 0 &&
	    sensor_channel_get(vref, SENSOR_CHAN_VOLTAGE, &v) == 0) {
		*mv = (int32_t)sensor_value_to_milli(&v);
		return true;
	}
#endif
	*mv = 0;
	return false;
}

static void link_arm(void *ctx, bool armed)
{
	ARG_UNUSED(ctx);
	(void)pod_gas_arm(armed);
}

static void load_link_identity(enum pod_position pos)
{
	const struct link_cfg dflt = {.addr = CONFIG_PRAHARI_LINK_ADDR,
				      .slot = CONFIG_PRAHARI_LINK_SLOT};
	struct link_cfg c;
	enum link_cfg_source src = LINK_CFG_SRC_KCONFIG;
	const uint8_t *bp = NULL;
	uint8_t blob[LINK_CFG_BLOB_LEN];

#if HAVE_EEPROM_POSITION
	const struct device *eep = DEVICE_DT_GET(EEPROM_NODE);

	if (device_is_ready(eep) &&
	    eeprom_read(eep, LINK_CFG_EEPROM_OFFSET, blob, sizeof(blob)) == 0) {
		bp = blob;
	}
#endif
	(void)link_cfg_resolve(bp, bp ? sizeof(blob) : 0, &dflt, &c, &src);
	link_id.addr = c.addr;
	link_id.slot = c.slot;
	link_id.position = (uint8_t)pos;
	printk("link: %s addr=%u slot=%u (%s)\n", link_mode_name(), c.addr, c.slot,
	       src == LINK_CFG_SRC_EEPROM ? "eeprom" : "kconfig default");
}

static void report_print(const struct pod_report *r)
{
	if (!IS_ENABLED(CONFIG_PRAHARI_FRAME_PRINT)) {
		return;
	}
	printk("report %u%s:", r->primary.cycle, r->wake ? " WAKE" : "");
	for (uint8_t p = 1; p <= PRAHARI_PARAM_INSITU_COUNT; p++) {
		uint8_t f = r->primary.flags[p];

		if (f & XDCR_F_VALID) {
			printk(" P%u=%d%s%s%s%s", p, r->primary.value[p],
			       (f & XDCR_F_UNCAL) ? "u" : "", (f & XDCR_F_RANGE) ? "R" : "",
			       (f & XDCR_F_ANOMALY) ? "!" : "", (f & XDCR_F_STALE) ? "s" : "");
		} else if (f) {
			printk(" P%u=%s", p, (f & XDCR_F_FAULT) ? "FAULT" : "NOPWR");
		}
	}
	for (int d = 0; d < DER_COUNT; d++) {
		if (r->derived_flags[d] & XDCR_F_VALID) {
			printk(" %s=%d%s", pod_derived_name(d), r->derived[d],
			       (r->derived_flags[d] & XDCR_F_RANGE) ? "R" : "");
		}
	}
	printk("  rail=%dmV%s fault=%x nopwr=%x range=%x load=%umA\n", r->self.rail_mv,
	       r->self.rail_valid ? "" : "?", r->self.xdcr_fault, r->self.xdcr_nopower,
	       r->self.xdcr_range, pwr_load_ma(&pwr));
}

static enum pod_position boot_position(enum pod_position_source *src)
{
	uint8_t blob[POD_CFG_BLOB_LEN];
	const uint8_t *bp = NULL;
	enum pod_position pos;

#if HAVE_EEPROM_POSITION
	const struct device *eep = DEVICE_DT_GET(EEPROM_NODE);

	if (device_is_ready(eep) && eeprom_read(eep, 0, blob, sizeof(blob)) == 0) {
		bp = blob;
	}
#endif
	(void)pod_position_resolve(bp, bp ? sizeof(blob) : 0, POD_POS_DEFAULT, &pos, src);
	return pos;
}

int main(void)
{
	enum pod_position_source src;
	enum pod_position pos = boot_position(&src);
	uint32_t now = k_uptime_get_32();
	uint32_t last_cycle = now;
	size_t n;
	int rc;

	printk("PRAHARI pod firmware, position %s (%s)\n", pod_position_name(pos),
	       src == POD_POS_SRC_EEPROM ? "eeprom" : "kconfig default");

	rc = pod_pwr_gpio_init();
	if (rc) {
		printk("load-switch gpio init failed: %d\n", rc);
	}
	rc = pwr_init(&pwr, pod_pwr_domains, pod_pwr_states, POD_PWR_DOMAIN_COUNT, &pod_pwr_backend,
		      CONFIG_PRAHARI_RAIL_BUDGET_MA, now);
	if (rc) {
		printk("power init failed: %d\n", rc);
	}

	n = xdcr_select(pod_xdcrs, POD_XDCR_COUNT, pos, selected, POD_XDCR_COUNT);
	printk("%u of %u transducers populated at %s:\n", (unsigned)n, (unsigned)POD_XDCR_COUNT,
	       pod_position_name(pos));
	for (size_t i = 0; i < n; i++) {
		const struct xdcr_desc *d = selected[i];

		rc = d->ops->init(d);
		if (rc && i < 16) {
			init_fail_bits |= (uint16_t)(1u << i);
		}
		printk("  %-16s %-8s rail=%s init=%d\n", d->name, xdcr_class_name(d->cls),
		       d->domain == XDCR_DOMAIN_NONE ? "passive" : pod_pwr_domains[d->domain].name,
		       rc);
	}

	sampler_init(&sampler, selected, n, &pwr, &clock, &frame);
	pwr_set_event_cb(&pwr, on_pwr_event, &sampler);

	load_calibration();
	{
		const struct pipeline_cfg pcfg = {
			.calib = &calib,
			.ranges = pod_ranges,
			.n_ranges = pod_range_count,
			.z_thr_centi = CONFIG_PRAHARI_ZGATE_THRESHOLD_CENTI,
			.z_floor_permille = CONFIG_PRAHARI_ZGATE_STD_FLOOR_PERMILLE,
		};

		rc = pipeline_init(&pipeline, &pcfg, selected, n);
		if (rc) {
			printk("pipeline init failed: %d (raise PRAHARI_MAX_CHANNELS)\n", rc);
		}
	}

	if (IS_ENABLED(CONFIG_PRAHARI_MOX_ARMED_AT_BOOT)) {
		(void)pod_gas_arm(true);
	}

	load_link_identity(pos);
	rc = link_init(&link_id, link_arm, NULL);
	if (rc) {
		printk("link init failed: %d (pod still senses; nothing leaves)\n", rc);
	}

	while (1) {
		now = k_uptime_get_32();
		pwr_tick(&pwr, now);
		if ((uint32_t)(now - last_cycle) >= (uint32_t)CONFIG_PRAHARI_SAMPLE_PERIOD_S * 1000u) {
			last_cycle = now;
			int32_t rail_mv;
			bool rail_ok;

			(void)sampler_cycle(&sampler);
			rail_ok = read_rail_mv(&rail_mv);
			pipeline_run(&pipeline, &frame, selected, n, rail_mv, rail_ok,
				     init_fail_bits, &report);
			report_print(&report);
			(void)link_publish(&report);
		}
		link_service(k_uptime_get_32());
		link_wait(K_MSEC(1000));
	}
	return 0;
}
```

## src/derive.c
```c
/* SPDX-License-Identifier: Apache-2.0 */
#include <errno.h>
#include <math.h>
#include <prahari/derive.h>

#define MAGNUS_A 17.625f
#define MAGNUS_B 243.04f
#define MAGNUS_ES0_KPA 0.61094f
#define PI_F 3.14159265358979f

static int32_t roundf_i32(float v)
{
	return (int32_t)(v >= 0 ? v + 0.5f : v - 0.5f);
}

int derive_vpd_dewpoint(int32_t t_mc, int32_t rh_mpct, int32_t *vpd_mkpa, int32_t *td_mc)
{
	float t = t_mc / 1000.0f;
	float rh = rh_mpct / 1000.0f;
	float es, ea, gamma, td;

	if (t <= -MAGNUS_B) {
		return -EINVAL;
	}
	if (rh < 0.1f) {
		rh = 0.1f; /* log(0) guard; RH below 0.1 % is not physical */
	} else if (rh > 100.0f) {
		rh = 100.0f;
	}
	es = MAGNUS_ES0_KPA * expf(MAGNUS_A * t / (t + MAGNUS_B));
	ea = es * rh / 100.0f;
	gamma = logf(rh / 100.0f) + MAGNUS_A * t / (t + MAGNUS_B);
	td = MAGNUS_B * gamma / (MAGNUS_A - gamma);

	if (vpd_mkpa) {
		*vpd_mkpa = roundf_i32((es - ea) * 1000.0f);
	}
	if (td_mc) {
		*td_mc = roundf_i32(td * 1000.0f);
	}
	return 0;
}

int derive_wind_uv(int32_t speed_mms, int32_t dir_mdeg, int32_t *u_mms, int32_t *v_mms,
		   int32_t *sin_milli, int32_t *cos_milli)
{
	float s = speed_mms / 1000.0f;
	float th = (dir_mdeg / 1000.0f) * (PI_F / 180.0f);
	float sn = sinf(th), cs = cosf(th);

	if (speed_mms < 0) {
		return -EINVAL;
	}
	if (u_mms) {
		*u_mms = roundf_i32(-s * sn * 1000.0f);
	}
	if (v_mms) {
		*v_mms = roundf_i32(-s * cs * 1000.0f);
	}
	if (sin_milli) {
		*sin_milli = roundf_i32(sn * 1000.0f);
	}
	if (cos_milli) {
		*cos_milli = roundf_i32(cs * 1000.0f);
	}
	return 0;
}

int derive_heat_index(int32_t t_mc, int32_t rh_mpct, int32_t *hi_mc)
{
	float tf = (t_mc / 1000.0f) * 9.0f / 5.0f + 32.0f;
	float rh = rh_mpct / 1000.0f;
	float hi;

	if (!hi_mc) {
		return -EINVAL;
	}
	if (rh < 0.0f) {
		rh = 0.0f;
	} else if (rh > 100.0f) {
		rh = 100.0f;
	}

	/* Steadman simple form; NWS uses it below HI 80 F. */
	hi = 0.5f * (tf + 61.0f + (tf - 68.0f) * 1.2f + rh * 0.094f);
	if (hi >= 80.0f) {
		float t2 = tf * tf, r2 = rh * rh;

		hi = -42.379f + 2.04901523f * tf + 10.14333127f * rh - 0.22475541f * tf * rh -
		     6.83783e-3f * t2 - 5.481717e-2f * r2 + 1.22874e-3f * t2 * rh +
		     8.5282e-4f * tf * r2 - 1.99e-6f * t2 * r2;
		if (rh < 13.0f && tf >= 80.0f && tf <= 112.0f) {
			float a = fabsf(tf - 95.0f);

			hi -= ((13.0f - rh) / 4.0f) * sqrtf((17.0f - a) / 17.0f);
		} else if (rh > 85.0f && tf >= 80.0f && tf <= 87.0f) {
			hi += ((rh - 85.0f) / 10.0f) * ((87.0f - tf) / 5.0f);
		}
	}
	*hi_mc = roundf_i32((hi - 32.0f) * 5.0f / 9.0f * 1000.0f);
	return 0;
}
```
